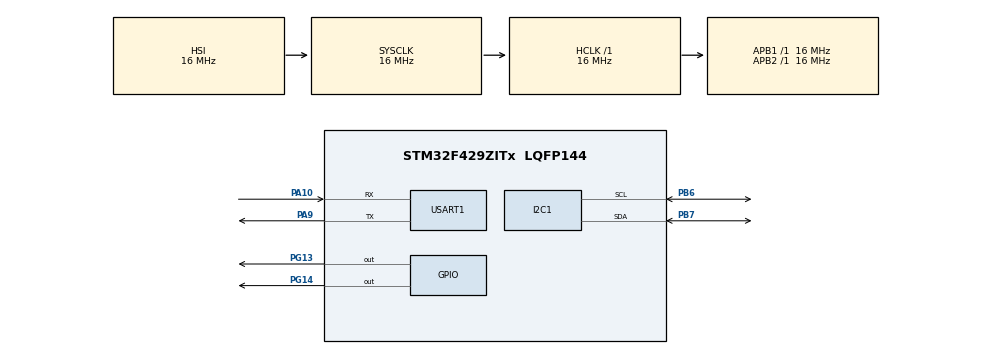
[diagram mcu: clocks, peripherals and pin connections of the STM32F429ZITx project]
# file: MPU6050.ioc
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Mcu.Family=STM32F4
Mcu.Name=STM32F429ZITx
Mcu.Package=LQFP144
NVIC.PriorityGroup=NVIC_PRIORITYGROUP_4
NVIC.TIM3_IRQn=true\:0\:0\:false\:false\:true\:true\:true
NVIC.TIM4_IRQn=true\:0\:0\:false\:false\:true\:true\:true
PA10.Mode=Asynchronous
PA10.Signal=USART1_RX
PA13.Mode=Serial_Wire
PA13.Signal=SYS_JTMS-SWDIO
PA14.Mode=Serial_Wire
PA14.Signal=SYS_JTCK-SWCLK
PA9.Mode=Asynchronous
PA9.Signal=USART1_TX
PB6.Mode=I2C
PB6.Signal=I2C1_SCL
PB7.Mode=I2C
PB7.Signal=I2C1_SDA
PG13.Signal=GPIO_Output
PG14.Signal=GPIO_Output
ProjectManager.HeapSize=0x200
ProjectManager.StackSize=0x400
ProjectManager.TargetToolchain=STM32CubeIDE
RCC.AHBFreq_Value=16000000
RCC.APB1Freq_Value=16000000
RCC.APB2Freq_Value=16000000
RCC.CortexFreq_Value=16000000
RCC.HSE_VALUE=25000000
RCC.HSI_VALUE=16000000
RCC.LSE_VALUE=32768
RCC.SYSCLKFreq_VALUE=16000000
RCC.VCOOutputFreq_Value=192000000
TIM3.Period=10000-1
TIM3.Prescaler=800-1
TIM4.Period=10000-1
TIM4.Prescaler=16-1
USART1.VirtualMode=VM_ASYNC
VP_TIM3_VS_ClockSourceINT.Mode=Internal
VP_TIM4_VS_ClockSourceINT.Mode=Internal
board=custom

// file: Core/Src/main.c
/* USER CODE BEGIN Header */
/**
  ******************************************************************************
  * @file           : main.c
  * @brief          : Main program body
  ******************************************************************************
  * @attention
  *
  * <h2><center>&copy; Copyright (c) 2021 STMicroelectronics.
  * All rights reserved.</center></h2>
  *
  * This software component is licensed by ST under BSD 3-Clause license,
  * the "License"; You may not use this file except in compliance with the
  * License. You may obtain a copy of the License at:
  *                        opensource.org/licenses/BSD-3-Clause
  *
  ******************************************************************************
  */
/* USER CODE END Header */
#include "main.h"

/* USER CODE BEGIN Includes */
#include "MPU6050.h"
/* USER CODE END Includes */

I2C_HandleTypeDef hi2c1;

TIM_HandleTypeDef htim3;
TIM_HandleTypeDef htim4;

/* USER CODE BEGIN PV */
MPU6050 Gyro;
/* USER CODE END PV */

void SystemClock_Config(void);
static void MX_GPIO_Init(void);
static void MX_USART1_UART_Init(void);
static void MX_I2C1_Init(void);
static void MX_TIM3_Init(void);
static void MX_TIM4_Init(void);

/* USER CODE BEGIN 0 */
PUTCHAR_PROTOTYPE
{
	while (LL_USART_IsActiveFlag_TC(USART1)==0)
	{}
	LL_USART_TransmitData8(USART1,(uint8_t)ch);

  	return ch;
}
/* USER CODE END 0 */

int main(void)
{

  /* MCU Configuration--------------------------------------------------------*/

  /* Reset of all peripherals, Initializes the Flash interface and the Systick. */
  HAL_Init();

  /* Configure the system clock */
  SystemClock_Config();

  /* Initialize all configured peripherals */
  MX_GPIO_Init();
  MX_USART1_UART_Init();
  MX_I2C1_Init();
  MX_TIM3_Init();
  MX_TIM4_Init();
  /* USER CODE BEGIN 2 */
  MPU6050_Init();
  HAL_TIM_Base_Start_IT(&htim3);
  HAL_TIM_Base_Start_IT(&htim4);
  /* USER CODE END 2 */

  /* Infinite loop */
  while (1)
  {
	  if(flag == 1)
	  {
		  MPU6050_Read_Gyro(&Gyro);
		  printf("Gia tri Gyroscope: x = %f, y = %f, z = %f \n",Gyro.x,Gyro.y,Gyro.z);
	  }
  }
}

void SystemClock_Config(void)
{
  RCC_OscInitTypeDef RCC_OscInitStruct = {0};
  RCC_ClkInitTypeDef RCC_ClkInitStruct = {0};

  /** Configure the main internal regulator output voltage
  */
  __HAL_RCC_PWR_CLK_ENABLE();
  __HAL_PWR_VOLTAGESCALING_CONFIG(PWR_REGULATOR_VOLTAGE_SCALE3);
  /** Initializes the RCC Oscillators according to the specified parameters
  * in the RCC_OscInitTypeDef structure.
  */
  RCC_OscInitStruct.OscillatorType = RCC_OSCILLATORTYPE_HSI;
  RCC_OscInitStruct.HSIState = RCC_HSI_ON;
  RCC_OscInitStruct.HSICalibrationValue = RCC_HSICALIBRATION_DEFAULT;
  RCC_OscInitStruct.PLL.PLLState = RCC_PLL_NONE;
  if (HAL_RCC_OscConfig(&RCC_OscInitStruct) != HAL_OK)
  {
    Error_Handler();
  }
  /** Initializes the CPU, AHB and APB buses clocks
  */
  RCC_ClkInitStruct.ClockType = RCC_CLOCKTYPE_HCLK|RCC_CLOCKTYPE_SYSCLK
                              |RCC_CLOCKTYPE_PCLK1|RCC_CLOCKTYPE_PCLK2;
  RCC_ClkInitStruct.SYSCLKSource = RCC_SYSCLKSOURCE_HSI;
  RCC_ClkInitStruct.AHBCLKDivider = RCC_SYSCLK_DIV1;
  RCC_ClkInitStruct.APB1CLKDivider = RCC_HCLK_DIV1;
  RCC_ClkInitStruct.APB2CLKDivider = RCC_HCLK_DIV1;

  if (HAL_RCC_ClockConfig(&RCC_ClkInitStruct, FLASH_LATENCY_0) != HAL_OK)
  {
    Error_Handler();
  }
}

static void MX_I2C1_Init(void)
{

  hi2c1.Instance = I2C1;
  hi2c1.Init.ClockSpeed = 100000;
  hi2c1.Init.DutyCycle = I2C_DUTYCYCLE_2;
  hi2c1.Init.OwnAddress1 = 0;
  hi2c1.Init.AddressingMode = I2C_ADDRESSINGMODE_7BIT;
  hi2c1.Init.DualAddressMode = I2C_DUALADDRESS_DISABLE;
  hi2c1.Init.OwnAddress2 = 0;
  hi2c1.Init.GeneralCallMode = I2C_GENERALCALL_DISABLE;
  hi2c1.Init.NoStretchMode = I2C_NOSTRETCH_DISABLE;
  if (HAL_I2C_Init(&hi2c1) != HAL_OK)
  {
    Error_Handler();
  }
  /** Configure Analogue filter
  */
  if (HAL_I2CEx_ConfigAnalogFilter(&hi2c1, I2C_ANALOGFILTER_ENABLE) != HAL_OK)
  {
    Error_Handler();
  }
  /** Configure Digital filter
  */
  if (HAL_I2CEx_ConfigDigitalFilter(&hi2c1, 0) != HAL_OK)
  {
    Error_Handler();
  }

}

static void MX_TIM3_Init(void)
{

  TIM_ClockConfigTypeDef sClockSourceConfig = {0};
  TIM_MasterConfigTypeDef sMasterConfig = {0};

  htim3.Instance = TIM3;
  htim3.Init.Prescaler = 800-1;
  htim3.Init.CounterMode = TIM_COUNTERMODE_UP;
  htim3.Init.Period = 10000-1;
  htim3.Init.ClockDivision = TIM_CLOCKDIVISION_DIV1;
  htim3.Init.AutoReloadPreload = TIM_AUTORELOAD_PRELOAD_DISABLE;
  if (HAL_TIM_Base_Init(&htim3) != HAL_OK)
  {
    Error_Handler();
  }
  sClockSourceConfig.ClockSource = TIM_CLOCKSOURCE_INTERNAL;
  if (HAL_TIM_ConfigClockSource(&htim3, &sClockSourceConfig) != HAL_OK)
  {
    Error_Handler();
  }
  sMasterConfig.MasterOutputTrigger = TIM_TRGO_RESET;
  sMasterConfig.MasterSlaveMode = TIM_MASTERSLAVEMODE_DISABLE;
  if (HAL_TIMEx_MasterConfigSynchronization(&htim3, &sMasterConfig) != HAL_OK)
  {
    Error_Handler();
  }

}

static void MX_TIM4_Init(void)
{

  TIM_ClockConfigTypeDef sClockSourceConfig = {0};
  TIM_MasterConfigTypeDef sMasterConfig = {0};

  htim4.Instance = TIM4;
  htim4.Init.Prescaler = 16-1;
  htim4.Init.CounterMode = TIM_COUNTERMODE_UP;
  htim4.Init.Period = 10000-1;
  htim4.Init.ClockDivision = TIM_CLOCKDIVISION_DIV1;
  htim4.Init.AutoReloadPreload = TIM_AUTORELOAD_PRELOAD_DISABLE;
  if (HAL_TIM_Base_Init(&htim4) != HAL_OK)
  {
    Error_Handler();
  }
  sClockSourceConfig.ClockSource = TIM_CLOCKSOURCE_INTERNAL;
  if (HAL_TIM_ConfigClockSource(&htim4, &sClockSourceConfig) != HAL_OK)
  {
    Error_Handler();
  }
  sMasterConfig.MasterOutputTrigger = TIM_TRGO_RESET;
  sMasterConfig.MasterSlaveMode = TIM_MASTERSLAVEMODE_DISABLE;
  if (HAL_TIMEx_MasterConfigSynchronization(&htim4, &sMasterConfig) != HAL_OK)
  {
    Error_Handler();
  }

}

static void MX_USART1_UART_Init(void)
{

  LL_USART_InitTypeDef USART_InitStruct = {0};

  LL_GPIO_InitTypeDef GPIO_InitStruct = {0};

  /* Peripheral clock enable */
  LL_APB2_GRP1_EnableClock(LL_APB2_GRP1_PERIPH_USART1);

  LL_AHB1_GRP1_EnableClock(LL_AHB1_GRP1_PERIPH_GPIOA);
  /**USART1 GPIO Configuration
  PA9   ------> USART1_TX
  PA10   ------> USART1_RX
  */
  GPIO_InitStruct.Pin = LL_GPIO_PIN_9|LL_GPIO_PIN_10;
  GPIO_InitStruct.Mode = LL_GPIO_MODE_ALTERNATE;
  GPIO_InitStruct.Speed = LL_GPIO_SPEED_FREQ_VERY_HIGH;
  GPIO_InitStruct.OutputType = LL_GPIO_OUTPUT_PUSHPULL;
  GPIO_InitStruct.Pull = LL_GPIO_PULL_NO;
  GPIO_InitStruct.Alternate = LL_GPIO_AF_7;
  LL_GPIO_Init(GPIOA, &GPIO_InitStruct);

  USART_InitStruct.BaudRate = 115200;
  USART_InitStruct.DataWidth = LL_USART_DATAWIDTH_8B;
  USART_InitStruct.StopBits = LL_USART_STOPBITS_1;
  USART_InitStruct.Parity = LL_USART_PARITY_NONE;
  USART_InitStruct.TransferDirection = LL_USART_DIRECTION_TX_RX;
  USART_InitStruct.HardwareFlowControl = LL_USART_HWCONTROL_NONE;
  USART_InitStruct.OverSampling = LL_USART_OVERSAMPLING_16;
  LL_USART_Init(USART1, &USART_InitStruct);
  LL_USART_ConfigAsyncMode(USART1);
  LL_USART_Enable(USART1);

}

static void MX_GPIO_Init(void)
{
  GPIO_InitTypeDef GPIO_InitStruct = {0};

  /* GPIO Ports Clock Enable */
  __HAL_RCC_GPIOA_CLK_ENABLE();
  __HAL_RCC_GPIOG_CLK_ENABLE();
  __HAL_RCC_GPIOB_CLK_ENABLE();

  /*Configure GPIO pin Output Level */
  HAL_GPIO_WritePin(GPIOG, GPIO_PIN_13|GPIO_PIN_14, GPIO_PIN_RESET);

  /*Configure GPIO pins : PG13 PG14 */
  GPIO_InitStruct.Pin = GPIO_PIN_13|GPIO_PIN_14;
  GPIO_InitStruct.Mode = GPIO_MODE_OUTPUT_PP;
  GPIO_InitStruct.Pull = GPIO_NOPULL;
  GPIO_InitStruct.Speed = GPIO_SPEED_FREQ_LOW;
  HAL_GPIO_Init(GPIOG, &GPIO_InitStruct);

}

void Error_Handler(void)
{
  __disable_irq();
  while (1)
  {
  }
}

/************************ (C) COPYRIGHT STMicroelectronics *****END OF FILE****/
